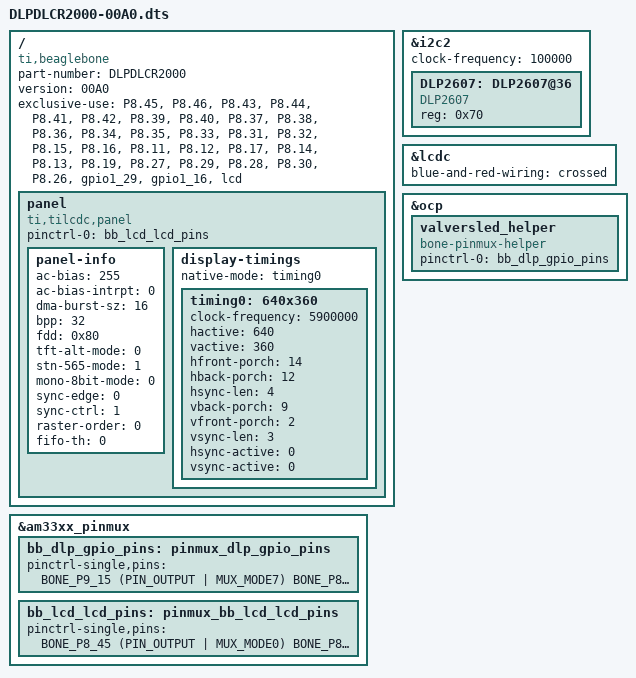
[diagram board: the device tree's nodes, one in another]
/*
 * Copyright (C) 2012 Texas Instruments Incorporated - http://www.ti.com/
 *
 * This program is free software; you can redistribute it and/or modify
 * it under the terms of the GNU General Public License version 2 as
 * published by the Free Software Foundation.
 */
/dts-v1/;
/plugin/;

#include <dt-bindings/board/am335x-bbw-bbb-base.h>
#include <dt-bindings/gpio/gpio.h>
#include <dt-bindings/pinctrl/am33xx.h>

/ {
	compatible = "ti,beaglebone", "ti,beaglebone-black", "ti,beaglebone-green";

	/* identification */
	part-number = "DLPDLCR2000";
	version = "00A0";

	/* state the resources this cape uses */
	exclusive-use =
		/* the pin header uses */
		"P8.45",	/* lcd: lcd_data0 */
		"P8.46",	/* lcd: lcd_data1 */
		"P8.43",	/* lcd: lcd_data2 */
		"P8.44",	/* lcd: lcd_data3 */
		"P8.41",	/* lcd: lcd_data4 */
		"P8.42",	/* lcd: lcd_data5 */
		"P8.39",	/* lcd: lcd_data6 */
		"P8.40",	/* lcd: lcd_data7 */
		"P8.37",	/* lcd: lcd_data8 */
		"P8.38",	/* lcd: lcd_data9 */
		"P8.36",	/* lcd: lcd_data10 */
		"P8.34",	/* lcd: lcd_data11 */
		"P8.35",	/* lcd: lcd_data12 */
		"P8.33",	/* lcd: lcd_data13 */
		"P8.31",	/* lcd: lcd_data14 */
		"P8.32",	/* lcd: lcd_data15 */

		"P8.15",	/* gpmc_ad15.lcd_data16 */
		"P8.16",	/* gpmc_ad14.lcd_data17 */
		"P8.11",	/* gpmc_ad13.lcd_data18 */
		"P8.12",	/* gpmc_ad12.lcd_data19 */
		"P8.17",	/* gpmc_ad11.lcd_data20 */
		"P8.14",	/* gpmc_ad10.lcd_data21 */
		"P8.13",	/* gpmc_ad9.lcd_data22 */
		"P8.19",	/* gpmc_ad8.lcd_data23 */

		"P8.27",	/* lcd: lcd_vsync */
		"P8.29",	/* lcd: lcd_hsync */
		"P8.28",	/* lcd: lcd_pclk */
		"P8.30",	/* lcd: lcd_ac_bias_en */

                "P8.26",	/* GPIO: INIT_DONE /*
		"P9.15",	/* GPIO: PROJ_ON_EXT /*
	
          	/* the hardware IP uses */
 	
                "gpio1_29",
                "gpio1_16",	
		"lcd";

	fragment@0 {
		target = <&am33xx_pinmux>;
		__overlay__ {

                        bb_dlp_gpio_pins: pinmux_dlp_gpio_pins {
                                 pinctrl-single,pins = <
                                        BONE_P9_15 (PIN_OUTPUT | MUX_MODE7) 
                                        BONE_P8_26 (PIN_INPUT_PULLDOWN | MUX_MODE7)

                                 >;
                         };


			bb_lcd_lcd_pins: pinmux_bb_lcd_lcd_pins {
				pinctrl-single,pins = <
					BONE_P8_45 (PIN_OUTPUT | MUX_MODE0) /* lcd_data0.lcd_data0 */
					BONE_P8_46 (PIN_OUTPUT | MUX_MODE0) /* lcd_data1.lcd_data1 */
					BONE_P8_43 (PIN_OUTPUT | MUX_MODE0) /* lcd_data2.lcd_data2 */
					BONE_P8_44 (PIN_OUTPUT | MUX_MODE0) /* lcd_data3.lcd_data3 */
					BONE_P8_41 (PIN_OUTPUT | MUX_MODE0) /* lcd_data4.lcd_data4 */
					BONE_P8_42 (PIN_OUTPUT | MUX_MODE0) /* lcd_data5.lcd_data5 */
					BONE_P8_39 (PIN_OUTPUT | MUX_MODE0) /* lcd_data6.lcd_data6 */
					BONE_P8_40 (PIN_OUTPUT | MUX_MODE0) /* lcd_data7.lcd_data7 */
					BONE_P8_37 (PIN_OUTPUT | MUX_MODE0) /* lcd_data8.lcd_data8 */
					BONE_P8_38 (PIN_OUTPUT | MUX_MODE0) /* lcd_data9.lcd_data9 */
					BONE_P8_36 (PIN_OUTPUT | MUX_MODE0) /* lcd_data10.lcd_data10 */
					BONE_P8_34 (PIN_OUTPUT | MUX_MODE0) /* lcd_data11.lcd_data11 */
					BONE_P8_35 (PIN_OUTPUT | MUX_MODE0) /* lcd_data12.lcd_data12 */
					BONE_P8_33 (PIN_OUTPUT | MUX_MODE0) /* lcd_data13.lcd_data13 */
					BONE_P8_31 (PIN_OUTPUT | MUX_MODE0) /* lcd_data14.lcd_data14 */
					BONE_P8_32 (PIN_OUTPUT | MUX_MODE0) /* lcd_data15.lcd_data15 */

					BONE_P8_15 (PIN_OUTPUT | MUX_MODE1) /* gpmc_ad15.lcd_data16 */
					BONE_P8_16 (PIN_OUTPUT | MUX_MODE1) /* gpmc_ad14.lcd_data17 */
					BONE_P8_11 (PIN_OUTPUT | MUX_MODE1) /* gpmc_ad13.lcd_data18 */
					BONE_P8_12 (PIN_OUTPUT | MUX_MODE1) /* gpmc_ad12.lcd_data19 */
					BONE_P8_17 (PIN_OUTPUT | MUX_MODE1) /* gpmc_ad11.lcd_data20 */
					BONE_P8_14 (PIN_OUTPUT | MUX_MODE1) /* gpmc_ad10.lcd_data21 */
					BONE_P8_13 (PIN_OUTPUT | MUX_MODE1) /* gpmc_ad9.lcd_data22 */
					BONE_P8_19 (PIN_OUTPUT | MUX_MODE1) /* gpmc_ad8.lcd_data23 */

					BONE_P8_27 (PIN_OUTPUT | MUX_MODE0) /* lcd_vsync.lcd_vsync */
					BONE_P8_29 (PIN_OUTPUT | MUX_MODE0) /* lcd_hsync.lcd_hsync */
					BONE_P8_28 (PIN_OUTPUT | MUX_MODE0) /* lcd_pclk.lcd_pclk */
					BONE_P8_30 (PIN_OUTPUT | MUX_MODE0) /* lcd_ac_bias_en.lcd_ac_bias_en */
				>;
			};

			
		};
    };

	
    fragment@1 {
        target = <&i2c2>;
        __overlay__ {
            status = "okay";

            /* this is the configuration part */
            clock-frequency = <100000>;

            #address-cells = <1>;
            #size-cells = <0>;

            DLP2607: DLP2607@36 {
                  compatible = "DLP2607";
                  #address-cells = <1>;
                  #size-cells = <0>;
                  reg = <0x70>;
            };
        };
    }; 
   

	

	fragment@2 {
		target = <&lcdc>;
		__overlay__ {
			status = "okay";
			blue-and-red-wiring = "crossed";
		};
	};



	

	fragment@3 {
		target-path="/";
		__overlay__ {

			/* avoid stupid warning */
			#address-cells = <1>;
			#size-cells = <1>;

			

		

			

			/* DLP Cape*/
			panel {
				status = "okay";
				compatible = "ti,tilcdc,panel";
				pinctrl-names = "default";
				pinctrl-0 = <&bb_lcd_lcd_pins>;
				panel-info {
					ac-bias           = <255>;
					ac-bias-intrpt    = <0>;
					dma-burst-sz      = <16>;
					bpp               = <32>;
					fdd               = <0x80>;
					tft-alt-mode      = <0>;
					stn-565-mode      = <1>;
					mono-8bit-mode    = <0>;
					sync-edge         = <0>;
					sync-ctrl         = <1>;
					raster-order      = <0>;
					fifo-th           = <0>;
				};
				display-timings {
					native-mode = <&timing0>;
					timing0: 640x360 {
						clock-frequency = <5900000>;
						hactive = <640>;
						vactive = <360>;
						hfront-porch = <14>;
						hback-porch = <12>;
						hsync-len = <4>;
						vback-porch = <9>;
						vfront-porch = <2>;
						vsync-len = <3>;
						hsync-active = <0>;
						vsync-active  = <0>;
					};
				};
			};
		};
	};


        fragment@4 {
              target = <&ocp>;
               __overlay__ {
                    valversled_helper {
                               compatible = "bone-pinmux-helper";
                               pinctrl-names = "default";
                               pinctrl-0 = <&bb_dlp_gpio_pins>;
                               status = "okay";
                     };
              };
	};




};


